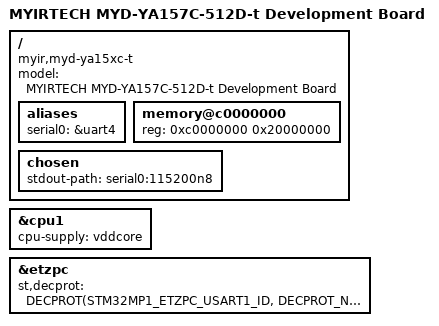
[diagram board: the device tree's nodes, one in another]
// SPDX-License-Identifier: (GPL-2.0+ OR BSD-3-Clause)


/dts-v1/;

#include "stm32mp157.dtsi"
#include "stm32mp15xa.dtsi"
#include "stm32mp15-ya15xc-t-pinctrl.dtsi"
#include "stm32mp15xxac-pinctrl.dtsi"
#include <dt-bindings/soc/st,stm32-etzpc.h>
#include "stm32mp15xx-ya15xc-t.dtsi"
#include "stm32mp15-ddr3-1x4Gb-1066-binG.dtsi" //512MiB DDR


/ {
	model = "MYIRTECH MYD-YA157C-512D-t Development Board";
	compatible = "myir,myd-ya15xc-t", "st,stm32mp157";
	
	aliases {
		serial0 = &uart4;
	};

	memory@c0000000 {
                device_type = "memory";
                reg = <0xc0000000 0x20000000>;
        };


	chosen {
		stdout-path = "serial0:115200n8";
	};
/*
	vdd_usb: fixedregulator@3 {
                compatible = "regulator-fixed";
                regulator-name = "vdd_usb";
                regulator-min-microvolt = <3300000>;
                regulator-max-microvolt = <3300000>;
                startup-delay-us = <70000>;
                regulator-boot-on;
                regulator-pull-down;
        };
*/

};

&cpu1{
	cpu-supply = <&vddcore>; //The second core
};

&etzpc {
	st,decprot = <
		DECPROT(STM32MP1_ETZPC_USART1_ID, DECPROT_NS_RW, DECPROT_UNLOCK)
		DECPROT(STM32MP1_ETZPC_SPI6_ID, DECPROT_NS_RW, DECPROT_UNLOCK)
		DECPROT(STM32MP1_ETZPC_I2C4_ID, DECPROT_NS_RW, DECPROT_UNLOCK)
		DECPROT(STM32MP1_ETZPC_I2C6_ID, DECPROT_NS_RW, DECPROT_UNLOCK)
		DECPROT(STM32MP1_ETZPC_RNG1_ID, DECPROT_NS_RW, DECPROT_UNLOCK)
		DECPROT(STM32MP1_ETZPC_HASH1_ID, DECPROT_NS_RW, DECPROT_UNLOCK)
		DECPROT(STM32MP1_ETZPC_DDRCTRL_ID, DECPROT_S_RW, DECPROT_LOCK)
		DECPROT(STM32MP1_ETZPC_DDRPHYC_ID, DECPROT_S_RW, DECPROT_LOCK)
		DECPROT(STM32MP1_ETZPC_STGENC_ID, DECPROT_S_RW, DECPROT_LOCK)
		DECPROT(STM32MP1_ETZPC_BKPSRAM_ID, DECPROT_S_RW, DECPROT_LOCK)
		DECPROT(STM32MP1_ETZPC_IWDG1_ID, DECPROT_S_RW, DECPROT_LOCK)
	>;
};
